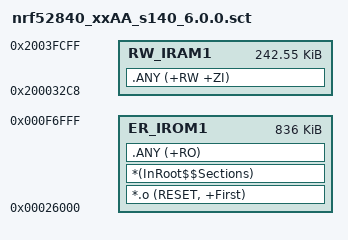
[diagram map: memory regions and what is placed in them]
; nRF5 SDK for Mesh Application scatter file -- Generated 2018-04-16 14:38:46 by tools/linker/linker_file_generator.py.
; 24 kB FLASH and 768 B RAM reserved for bootloader.
;
; This file is intended for nrf52840_xxAA with the s140_6.0.0 SoftDevice.

LR_IROM1 0x26000 0xd1000 {
  ER_IROM1 0x26000 0xd1000 {
   *.o (RESET, +First)
   *(InRoot$$Sections)
   .ANY (+RO)
  }

  RW_IRAM1 0x200032c8 0x3ca38 {
   .ANY (+RW +ZI)
  }
}
